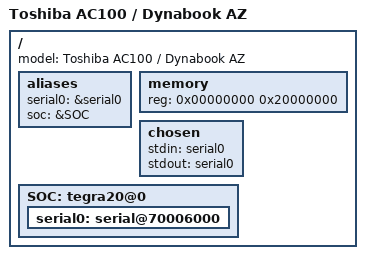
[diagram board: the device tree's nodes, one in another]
/*-
 * Copyright (c) 2011 The FreeBSD Foundation
 * Copyright (c) 2012 Andrew Turner
 * All rights reserved.
 *
 * Developed by Damjan Marion <damjan.marion@gmail.com>
 *
 * Redistribution and use in source and binary forms, with or without
 * modification, are permitted provided that the following conditions
 * are met:
 * 1. Redistributions of source code must retain the above copyright
 *    notice, this list of conditions and the following disclaimer.
 * 2. Redistributions in binary form must reproduce the above copyright
 *    notice, this list of conditions and the following disclaimer in the
 *    documentation and/or other materials provided with the distribution.
 *
 * THIS SOFTWARE IS PROVIDED BY THE AUTHOR AND CONTRIBUTORS ``AS IS'' AND
 * ANY EXPRESS OR IMPLIED WARRANTIES, INCLUDING, BUT NOT LIMITED TO, THE
 * IMPLIED WARRANTIES OF MERCHANTABILITY AND FITNESS FOR A PARTICULAR PURPOSE
 * ARE DISCLAIMED. IN NO EVENT SHALL THE AUTHOR OR CONTRIBUTORS BE LIABLE
 * FOR ANY DIRECT, INDIRECT, INCIDENTAL, SPECIAL, EXEMPLARY, OR CONSEQUENTIAL
 * DAMAGES (INCLUDING, BUT NOT LIMITED TO, PROCUREMENT OF SUBSTITUTE GOODS
 * OR SERVICES; LOSS OF USE, DATA, OR PROFITS; OR BUSINESS INTERRUPTION)
 * HOWEVER CAUSED AND ON ANY THEORY OF LIABILITY, WHETHER IN CONTRACT, STRICT
 * LIABILITY, OR TORT (INCLUDING NEGLIGENCE OR OTHERWISE) ARISING IN ANY WAY
 * OUT OF THE USE OF THIS SOFTWARE, EVEN IF ADVISED OF THE POSSIBILITY OF
 * SUCH DAMAGE.
 * 
 * $FreeBSD$
 */
/dts-v1/;

/include/ "tegra20.dtsi"

/ {
	model = "Toshiba AC100 / Dynabook AZ";

	aliases {
		serial0 = &serial0;
		soc = &SOC;
	};

	memory {
		device_type = "memory";
		reg = < 0x00000000 0x20000000 >;	/* 512MB RAM at 0x0 */
	};

	chosen {
		stdin = "serial0";
		stdout = "serial0";
	};

	SOC: tegra20@0 {
		serial0: serial@70006000 {
		};
	};
};

